VERSION ""

NS_ :

BS_:

BU_:

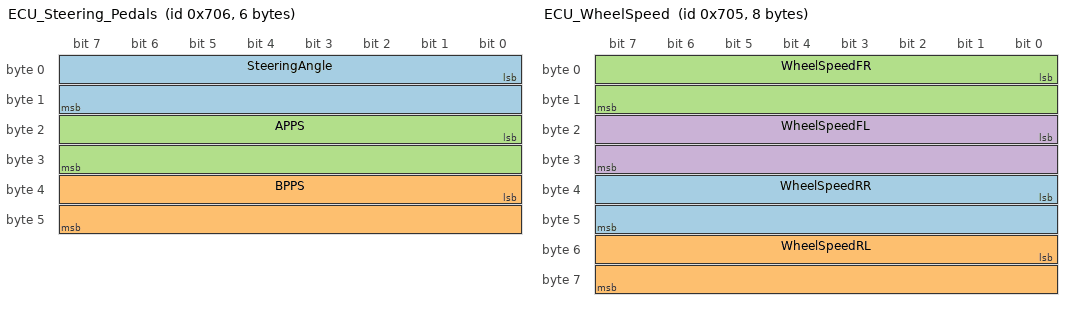
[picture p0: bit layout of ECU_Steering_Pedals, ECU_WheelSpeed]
BO_ 1798 ECU_Steering_Pedals: 6 Vector__XXX
 SG_ SteeringAngle : 0|16@1- (0.1,0) [0|0] "Degrees" Vector__XXX
 SG_ BPPS : 32|16@1- (1,0) [0|0] "Percent" Vector__XXX
 SG_ APPS : 16|16@1- (1,0) [0|0] "Percent" Vector__XXX

BO_ 1797 ECU_WheelSpeed: 8 Vector__XXX
 SG_ WheelSpeedRR : 32|16@1- (0.1,0) [0|0] "km/h" Vector__XXX
 SG_ WheelSpeedRL : 48|16@1- (0.1,0) [0|0] "km/h" Vector__XXX
 SG_ WheelSpeedFR : 0|16@1- (0.1,0) [0|0] "km/h" Vector__XXX
 SG_ WheelSpeedFL : 16|16@1- (0.1,0) [0|0] "km/h" Vector__XXX

BA_DEF_  "BusType" STRING ;
BA_DEF_DEF_  "BusType" "CAN";
